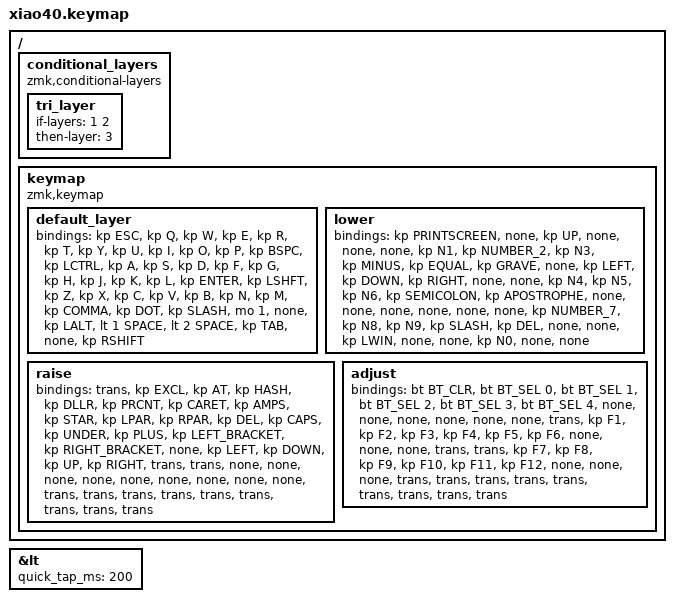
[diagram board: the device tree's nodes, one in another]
/*
 * Copyright (c) 2022 Ramon Imbao
 *
 * SPDX-License-Identifier: MIT
 */

#include <behaviors.dtsi>
#include <dt-bindings/zmk/keys.h>
#include <dt-bindings/zmk/bt.h>

// Using layer taps on thumbs, having quick tap as well helps w/ repeating space/backspace

&lt {
    quick_tap_ms = <200>;
};

/ {
    conditional_layers {
        compatible = "zmk,conditional-layers";

        tri_layer {
            if-layers = <1 2>;
            then-layer = <3>;
        };
    };

    keymap {
        compatible = "zmk,keymap";

        default_layer {
            bindings = <
 &kp ESC   &kp Q   &kp W   &kp E   &kp R   &kp T   &kp Y   &kp U   &kp I   &kp O   &kp P  &kp BSPC  &kp LCTRL   &kp A   &kp S   &kp D   &kp F   &kp G   &kp H   &kp J   &kp K   &kp L  &kp ENTER  &kp LSHFT   &kp Z   &kp X   &kp C   &kp V   &kp B   &kp N   &kp M  &kp COMMA  &kp DOT  &kp SLASH   &mo 1   &none  &kp LALT  &lt 1 SPACE  &lt 2 SPACE  &kp TAB   &none  &kp RSHIFT
            >;
        };

        lower {
            bindings = <
 &kp PRINTSCREEN   &none  &kp UP   &none   &none   &none  &kp N1  &kp NUMBER_2  &kp N3  &kp MINUS  &kp EQUAL  &kp GRAVE   &none  &kp LEFT  &kp DOWN  &kp RIGHT   &none   &none  &kp N4  &kp N5  &kp N6  &kp SEMICOLON  &kp APOSTROPHE   &none   &none   &none   &none   &none   &none  &kp NUMBER_7  &kp N8  &kp N9  &kp SLASH  &kp DEL   &none   &none  &kp LWIN   &none   &none  &kp N0   &none   &none
            >;
        };

        raise {
            bindings = <
 &trans  &kp EXCL  &kp AT  &kp HASH  &kp DLLR  &kp PRCNT  &kp CARET  &kp AMPS  &kp STAR  &kp LPAR  &kp RPAR  &kp DEL  &kp CAPS  &kp UNDER  &kp PLUS  &kp LEFT_BRACKET  &kp RIGHT_BRACKET   &none  &kp LEFT  &kp DOWN  &kp UP  &kp RIGHT  &trans  &trans   &none   &none   &none   &none   &none   &none   &none   &none   &none  &trans  &trans  &trans  &trans  &trans  &trans  &trans  &trans  &trans
            >;
        };

        adjust {
            bindings = <
 &bt BT_CLR  &bt BT_SEL 0  &bt BT_SEL 1  &bt BT_SEL 2  &bt BT_SEL 3  &bt BT_SEL 4   &none   &none   &none   &none   &none   &none  &trans  &kp F1  &kp F2  &kp F3  &kp F4  &kp F5  &kp F6   &none   &none   &none  &trans  &trans  &kp F7  &kp F8  &kp F9  &kp F10  &kp F11  &kp F12   &none   &none   &none  &trans  &trans  &trans  &trans  &trans  &trans  &trans  &trans  &trans
            >;
        };
    };
};
